# max32650 register map
Vendor: Maxim-Integrated; Series: ARMCM4; File version: 1.1
CPU: CM4 r2p1, little endian, MPU, FPU, 3 interrupt priority bits
Registers are 32-bit, read-write, reset 0x0 unless marked. A register's access mark holds for its fields unless they carry their own. Offsets are from the block's base; [hi:lo] are bit positions; {n}, {i} and the like mark numbered series; 'fields as' and 'values as' point back to an identical list.

## SDHC — SDHC/SDIO Controller
Base 0x40037000
0x00 SDMA — SDMA System Address / Argument 2.
  [31:0] ADDR — SDMA System Address / Argument 2 of Auto CMD23.
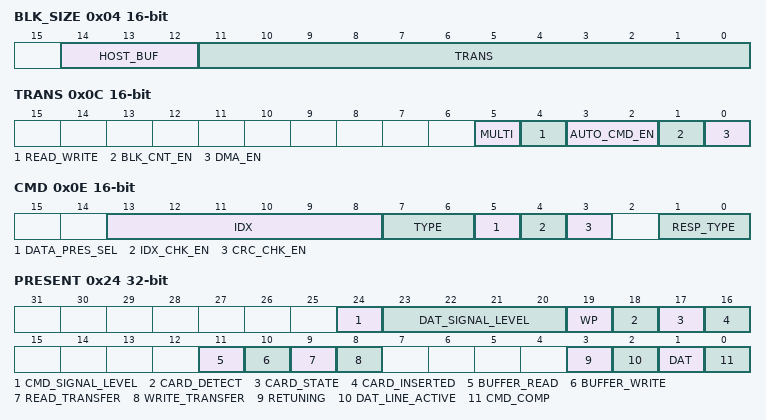
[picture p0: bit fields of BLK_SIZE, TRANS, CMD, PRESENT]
0x04 BLK_SIZE 16-bit — Block Size.
  [14:12] HOST_BUF — Host SDMA Buffer Boundary.
    0=4KB; 1=8KB; 2=16KB; 3=32KB; 4=64KB; 5=128KB; 6=256KB; 7=512KB
  [11:0] TRANS — Transfer Block Size.
0x06 BLK_CNT 16-bit — Block Count.
  [15:0] COUNT — Blocks Count For Current Transfer.
0x08 ARG_1 — Argument 1.
  [31:0] CMD — Command Argument 1.
0x0C TRANS 16-bit — Transfer Mode.
  [5] MULTI — Multi / Single Block Select.
    1=multi; 0=single
  [4] READ_WRITE — Data Transfer Direction Select.
    0=write; 1=read
  [3:2] AUTO_CMD_EN — Auto CMD Enable.
    0=disable; 1=cmd12; 2=cmd23
  [1] BLK_CNT_EN — Block Count Enable.
    0=dis; 1=en
  [0] DMA_EN — DMA Enable.
    0=dis; 1=en
0x0E CMD 16-bit — Command.
  [13:8] IDX — Command Index.
  [7:6] TYPE — Command Type.
    0=normal; 1=suspend; 2=resume; 3=abort
  [5] DATA_PRES_SEL — Data Present Select.
  [4] IDX_CHK_EN — Command Index Check Enable.
    1=en; 0=dis
  [3] CRC_CHK_EN — Command CRC Check Enable.
    1=en; 0=dis
  [1:0] RESP_TYPE — Response Type Select.
    0=none; 1=resp136; 2=resp48; 3=resp48_busy
{0x10+2i} RESP[{i}] (i=0..7) 16-bit — Response 0 Register 0-15.
  [15:0] CMD_RESP — Command Response.
0x20 BUFFER — Buffer Data Port.
  [31:0] DATA — Buffer Data.
0x24 PRESENT ro — Present State.
  [24] CMD_SIGNAL_LEVEL — CMD Line Signal Level.
  [23:20] DAT_SIGNAL_LEVEL — DAT[3:0] Line Signal Level.
  [19] WP — Write Protect Switch Pin Level.
  [18] CARD_DETECT — Card Detect Pin Level.
  [17] CARD_STATE — Card State Stable.
  [16] CARD_INSERTED
  [11] BUFFER_READ — Buffer Read Enable.
  [10] BUFFER_WRITE — Buffer Write Enable.
  [9] READ_TRANSFER — Read Transfer Active.
  [8] WRITE_TRANSFER — Write Transfer Active.
  [3] RETUNING — Re-Tuning Request.
  [2] DAT_LINE_ACTIVE
  [1] DAT — Command Inhibit (DAT).
  [0] CMD_COMP — Command Inhibit (CMD).
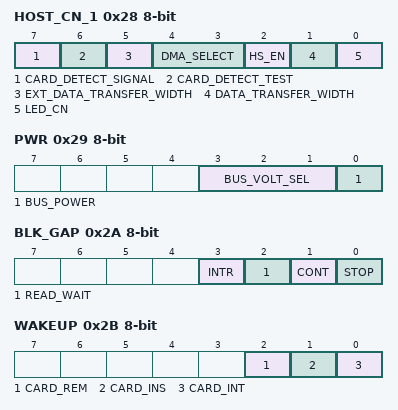
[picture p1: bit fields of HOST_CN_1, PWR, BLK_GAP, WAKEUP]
0x28 HOST_CN_1 8-bit — Host Control 1.
  [7] CARD_DETECT_SIGNAL — Card Detect Signal Selection.
  [6] CARD_DETECT_TEST — Card Detect Test Level.
  [5] EXT_DATA_TRANSFER_WIDTH — Extended Data Transfer Width.
  [4:3] DMA_SELECT
  [2] HS_EN — High Speed Enable.
  [1] DATA_TRANSFER_WIDTH
  [0] LED_CN — LED Control.
0x29 PWR 8-bit — Power Control.
  [3:1] BUS_VOLT_SEL — SD Bus Voltage Select.
    5=1v8_typ; 6=3v_typ; 7=3v3_typ
  [0] BUS_POWER — SD Bus Power.
0x2A BLK_GAP 8-bit — Block Gap Control.
  [3] INTR — Interrupt At Block Gap.
  [2] READ_WAIT — Read Wait Control.
  [1] CONT — Continue Request.
  [0] STOP — Stop At Block Gap Request.
0x2B WAKEUP 8-bit — Wakeup Control.
  [2] CARD_REM — Wakeup Event Enable On SD Card Removal.
  [1] CARD_INS — Wakeup Event Enable On SD Card Insertion.
  [0] CARD_INT — Wakeup Event Enable On Card Interrupt.
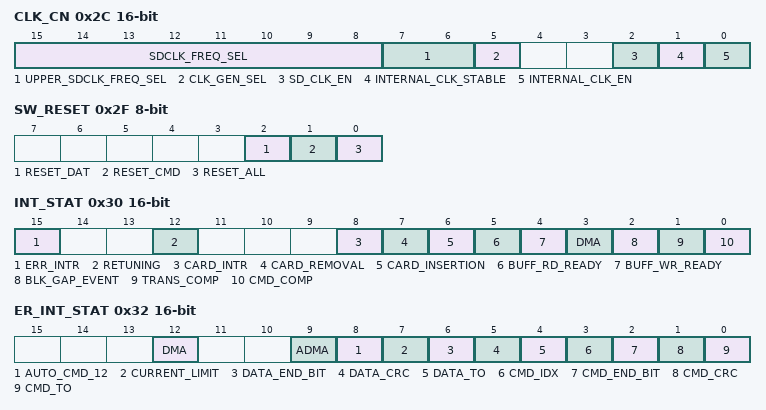
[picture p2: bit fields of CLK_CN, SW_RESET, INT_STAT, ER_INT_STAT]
0x2C CLK_CN 16-bit — Clock Control.
  [15:8] SDCLK_FREQ_SEL — SDCLK Frequency Select.
  [7:6] UPPER_SDCLK_FREQ_SEL — Upper Bits of SDCLK Frequency Select.
  [5] CLK_GEN_SEL ro — Clock Generator Select.
  [2] SD_CLK_EN — SD Clock Enable.
  [1] INTERNAL_CLK_STABLE ro — Internal Clock Stable.
  [0] INTERNAL_CLK_EN — Internal Clock Enable.
0x2E TO 8-bit — Timeout Control.
  [3:0] DATA_COUNT_VALUE — Data Timeout Counter Value.
    {v}=2POW{v+13} (v=0..14)
0x2F SW_RESET 8-bit — Software Reset.
  [2] RESET_DAT — Software Reset For DAT Line.
  [1] RESET_CMD — Software Reset For CMD Line.
  [0] RESET_ALL — Software Reset For All.
0x30 INT_STAT 16-bit — Normal Interrupt Status.
  [15] ERR_INTR — Error Interrupt.
  [12] RETUNING — Re-Tuning Event.
  [8] CARD_INTR — Card Interrupt.
  [7] CARD_REMOVAL
  [6] CARD_INSERTION
  [5] BUFF_RD_READY — Buffer Read Ready.
  [4] BUFF_WR_READY — Buffer Write Ready.
  [3] DMA — DMA Interrupt.
  [2] BLK_GAP_EVENT — Block Gap Event.
  [1] TRANS_COMP — Transfer Complete.
  [0] CMD_COMP — Command Complete.
0x32 ER_INT_STAT 16-bit — Error Interrupt Status.
  [12] DMA — DMA Error.
  [9] ADMA — ADMA Error.
  [8] AUTO_CMD_12 — Auto CMD Error.
  [7] CURRENT_LIMIT — Current Limit Error.
  [6] DATA_END_BIT — Data End Bit Error.
  [5] DATA_CRC — Data CRC Error.
  [4] DATA_TO — Data Timeout Error.
  [3] CMD_IDX — Command Index Error.
  [2] CMD_END_BIT — Command End Bit Error.
  [1] CMD_CRC — Command CRC Error.
  [0] CMD_TO — Command Timeout Error.
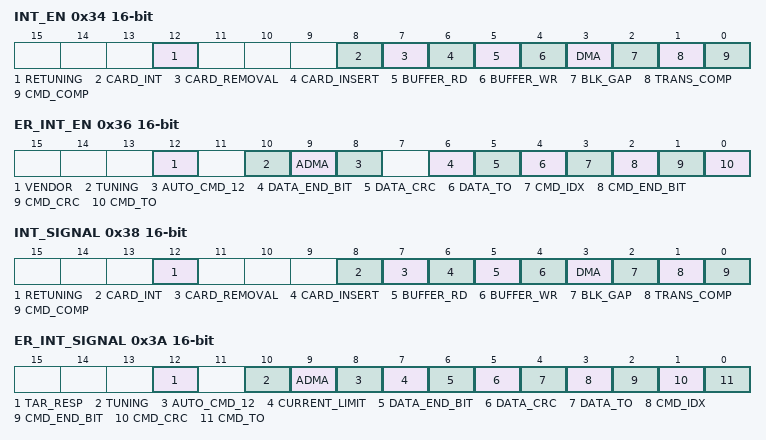
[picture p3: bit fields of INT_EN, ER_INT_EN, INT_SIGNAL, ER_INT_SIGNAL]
0x34 INT_EN 16-bit — Normal Interrupt Status Enable.
  [12] RETUNING — Re-Tuning Event Status Enable.
  [8] CARD_INT — Card Interrupt Status Enable.
  [7] CARD_REMOVAL — Card Removal Status Enable.
  [6] CARD_INSERT — Card Insertion Status Enable.
  [5] BUFFER_RD — Buffer Read Ready Status Enable.
  [4] BUFFER_WR — Buffer Write Ready Status Enable.
  [3] DMA — DMA Interrupt Status Enable.
  [2] BLK_GAP — Block Gap Event Status Enable.
  [1] TRANS_COMP — Transfer Complete Status Enable.
  [0] CMD_COMP — Command Complete Status Enable.
0x36 ER_INT_EN 16-bit — Error Interrupt Status Enable.
  [12] VENDOR — Vendor Specific Error Status Enable.
  [10] TUNING — Tuning Error Status Enable.
  [9] ADMA — ADMA Error Status Enable.
  [8] AUTO_CMD_12 — Auto CMD Error Status Enable.
  [6] DATA_END_BIT — Data End Bit Error Status Enable.
  [5] DATA_CRC — Data CRC Error Status Enable.
  [4] DATA_TO — Data Timeout Error Status Enable.
  [3] CMD_IDX — Command Index Error Status Enable.
  [2] CMD_END_BIT — Command End Bit Error Status Enable.
  [1] CMD_CRC — Command CRC Error Status Enable.
  [0] CMD_TO — Command Timeout Error Status Enable.
0x38 INT_SIGNAL 16-bit — Normal Interrupt Signal Enable.
  [12] RETUNING — Re-Tuning Event Signal Enable.
  [8] CARD_INT — Card Interrupt Signal Enable.
  [7] CARD_REMOVAL — Card Removal Signal Enable.
  [6] CARD_INSERT — Card Insertion Signal Enable.
  [5] BUFFER_RD — Buffer Read Ready Signal Enable.
  [4] BUFFER_WR — Buffer Write Ready Signal Enable.
  [3] DMA — DMA Interrupt Signal Enable.
  [2] BLK_GAP — Block Gap Event Signal Enable.
  [1] TRANS_COMP — Transfer Complete Signal Enable.
  [0] CMD_COMP — Command Complete Signal Enable.
0x3A ER_INT_SIGNAL 16-bit — Error Interrupt Signal Enable.
  [12] TAR_RESP — Target Response Error Signal Enable.
  [10] TUNING — Tuning Error Signal Enable.
  [9] ADMA — ADMA Error Signal Enable.
  [8] AUTO_CMD_12 — Auto CMD Error Signal Enable.
  [7] CURRENT_LIMIT — Current Limit Error Signal Enable.
  [6] DATA_END_BIT — Data End Bit Error Signal Enable.
  [5] DATA_CRC — Data CRC Error Signal Enable.
  [4] DATA_TO — Data Timeout Error Signal Enable.
  [3] CMD_IDX — Command Index Error Signal Enable.
  [2] CMD_END_BIT — Command End Bit Error Signal Enable.
  [1] CMD_CRC — Command CRC Error Signal Enable.
  [0] CMD_TO — Command Timeout Error Signal Enable.
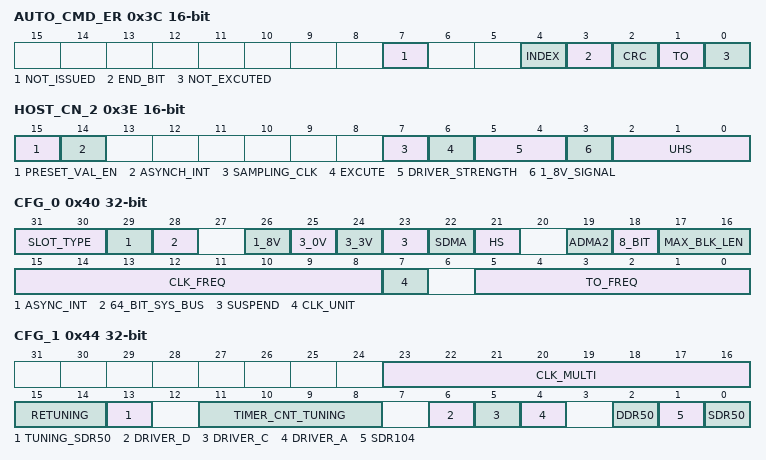
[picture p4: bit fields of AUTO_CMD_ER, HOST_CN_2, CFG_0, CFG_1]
0x3C AUTO_CMD_ER 16-bit — Auto CMD Error Status.
  [7] NOT_ISSUED — Command Not Issued By Auto CMD12 Error.
  [4] INDEX — Auto CMD Index Error.
  [3] END_BIT — Auto CMD End Bit Error.
  [2] CRC — Auto CMD CRC Error.
  [1] TO — Auto CMD Timeout Error.
  [0] NOT_EXCUTED — Auto CMD12 Not Executed.
0x3E HOST_CN_2 16-bit — Host Control 2.
  [15] PRESET_VAL_EN — Preset Value Enable.
  [14] ASYNCH_INT — Asynchronous Interrupt Enable.
  [7] SAMPLING_CLK — Sampling Clock Select.
  [6] EXCUTE — Execute Tuning.
  [5:4] DRIVER_STRENGTH — Driver Strength Select.
    0=typeB; 1=typeA; 2=typeC; 3=typrD
  [3] 1_8V_SIGNAL — 1.8V Signaling Enable.
  [2:0] UHS — UHS Mode Select.
    0=sdr12; 1=sdr25; 2=sdr50; 4=ddr50
0x40 CFG_0 ro — Capabilities 0-31.
  [31:30] SLOT_TYPE
  [29] ASYNC_INT — Asynchronous Interrupt Support.
  [28] 64_BIT_SYS_BUS — 64-bit System Bus Support.
  [26] 1_8V — Voltage Support 1.8V.
  [25] 3_0V — Voltage Support 3.0V.
  [24] 3_3V — Voltage Support 3.3V.
  [23] SUSPEND — Suspend/Resume Support.
  [22] SDMA — SDMA Support.
  [21] HS — High Speed Support.
  [19] ADMA2 — ADMA2 Support.
  [18] 8_BIT — 8-bit Support for Embedded Device.
  [17:16] MAX_BLK_LEN — Max Block Length.
    2=2048_bytes
  [15:8] CLK_FREQ — Base Clock Frequency For SD Clock.
  [7] CLK_UNIT — Timeout Clock Unit.
  [5:0] TO_FREQ — Timeout Clock Frequency.
    1=1mhz
0x44 CFG_1 ro — Capabilities 32-63.
  [23:16] CLK_MULTI — Clock Multiplier.
  [15:14] RETUNING — Re-Tuning Modes.
  [13] TUNING_SDR50 — Use Tuning for SDR50.
  [11:8] TIMER_CNT_TUNING — Timer Count for Re-Tuning.
    0=dis; 1=1sec; 2=2sec; 3=4sec; 4=8sec; 5=16sec; 6=32sec; 7=64sec; 8=128sec; 9=256sec; 10=512sec; 11=1024sec
  [6] DRIVER_D — Driver Type D Support.
  [5] DRIVER_C — Driver Type C Support.
  [4] DRIVER_A — Driver Type A Support.
  [2] DDR50 — DDR50 Support.
  [1] SDR104 — SDR104 Support.
  [0] SDR50 — SDR50 Support.
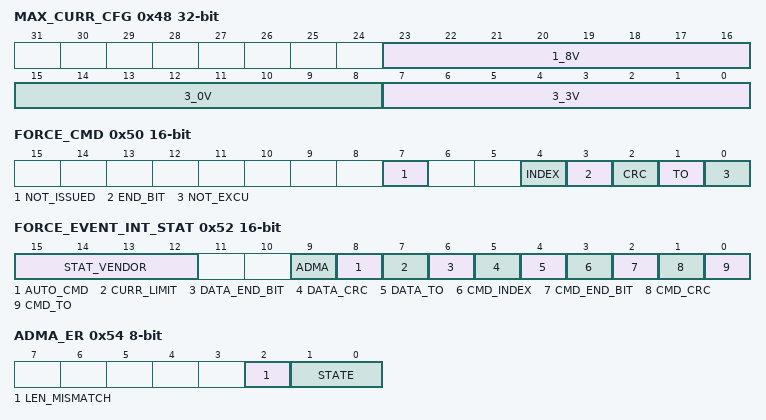
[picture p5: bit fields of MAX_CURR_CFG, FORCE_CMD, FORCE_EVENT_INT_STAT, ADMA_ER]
0x48 MAX_CURR_CFG ro — Maximum Current Capabilities.
  [23:16] 1_8V — Maximum Current for 1.8V.
  [15:8] 3_0V — Maximum Current for 3.0V.
  [7:0] 3_3V — Maximum Current for 3.3V.
0x50 FORCE_CMD 16-bit wo — Force Event for Auto CMD Error Status.
  [7] NOT_ISSUED — Force Event for Command Not Issued By Auto CMD12 Error.
  [4] INDEX — Force Event for Auto CMD Index Error.
  [3] END_BIT — Force Event for Auto CMD End Bit Error.
  [2] CRC — Force Event for Auto CMD CRC Error.
  [1] TO — Force Event for Auto CMD Timeout Error.
  [0] NOT_EXCU — Force Event for Auto CMD12 Not Executed.
0x52 FORCE_EVENT_INT_STAT 16-bit — Force Event for Error Interrupt Status.
  [15:12] STAT_VENDOR wo — Force Event for Vendor Specific Error Status.
  [9] ADMA — Force Event for ADMA Error.
  [8] AUTO_CMD ro — Force Event for Auto CMD Error.
  [7] CURR_LIMIT ro — Force Event for Current Limit Error.
  [6] DATA_END_BIT ro — Force Event for Data End Bit Error.
  [5] DATA_CRC ro — Force Event for Data CRC Error.
  [4] DATA_TO ro — Force Event for Data Timeout Error.
  [3] CMD_INDEX ro — Force Event for Command Index Error.
  [2] CMD_END_BIT ro — Force Event for Command End Bit Error.
  [1] CMD_CRC ro — Force Event for Command CRC Error.
  [0] CMD_TO ro — Force Event for Command Timeout Error.
0x54 ADMA_ER 8-bit — ADMA Error Status.
  [2] LEN_MISMATCH — ADMA Length Mismatch Error.
  [1:0] STATE — ADMA Error State.
0x58 ADMA_ADDR_0 — ADMA System Address 0-31.
  [31:0] ADDR — ADMA System Address Part 1 (part 2 is ADMA_ADDR_1).
0x5C ADMA_ADDR_1 — ADMA System Address 32-63.
  [31:0] ADDR — ADMA System Address Part 1 (part 2 is ADMA_ADDR_1).
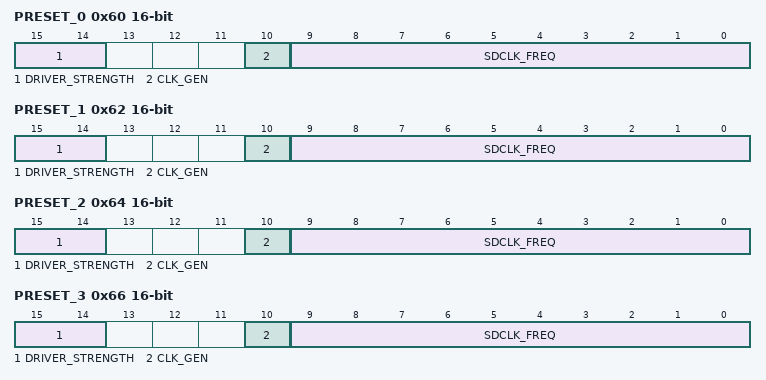
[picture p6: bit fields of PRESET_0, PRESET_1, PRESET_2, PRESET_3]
0x60 PRESET_0 16-bit ro — Preset Value for Initialization.
  [15:14] DRIVER_STRENGTH — Driver Strength Select Value.
    0=typeB; 1=typeA; 2=typeC; 3=typeD
  [10] CLK_GEN — Clock Generator Select Value.
  [9:0] SDCLK_FREQ — SDCLK Frequency Select Value.
0x62 PRESET_1 16-bit ro — Preset Value for Default Speed.
  fields as PRESET_0
0x64 PRESET_2 16-bit ro — Preset Value for High Speed.
  fields as PRESET_0
0x66 PRESET_3 16-bit ro — Preset Value for SDR12.
  fields as PRESET_0
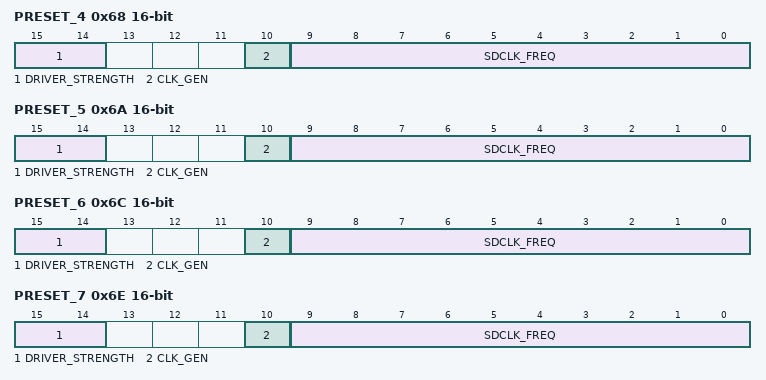
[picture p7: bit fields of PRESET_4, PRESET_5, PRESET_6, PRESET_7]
0x68 PRESET_4 16-bit ro — Preset Value for SDR25.
  fields as PRESET_0
0x6A PRESET_5 16-bit ro — Preset Value for SDR50.
  fields as PRESET_0
0x6C PRESET_6 16-bit ro — Preset Value for SDR104.
  fields as PRESET_0
0x6E PRESET_7 16-bit ro — Preset Value for DDR50.
  fields as PRESET_0
0xE0 SHARED_BUS
0xFC SLOT_INT 16-bit ro — Slot Interrupt Status.
  [0] INT_SIGNALS — Interrupt Signal For Each Slot.
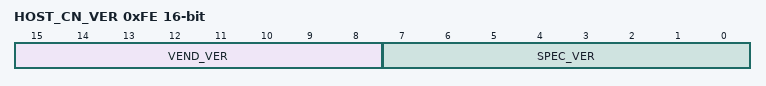
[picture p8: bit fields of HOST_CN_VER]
0xFE HOST_CN_VER 16-bit — Host Controller Version.
  [15:8] VEND_VER — Vendor Version Number.
  [7:0] SPEC_VER — Specification Version Number.
